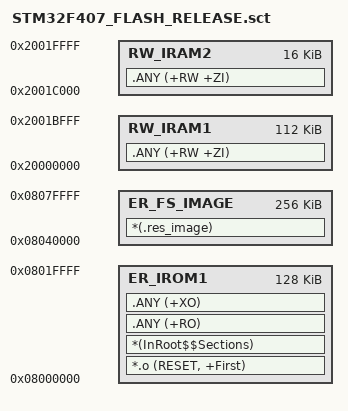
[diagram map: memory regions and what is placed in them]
; *************************************************************
; *** Scatter-Loading Description File generated by uVision ***
; *************************************************************

LR_IROM1 0x08000000 0x0020000  {    ; load region size_region
  ER_IROM1 0x08000000 0x0020000  {  ; load address = execution address
   *.o (RESET, +First)
   *(InRoot$$Sections)
   .ANY (+RO)
   .ANY (+XO)
  }
  RW_IRAM1 0x20000000 0x0001C000  {  ; RW data
   .ANY (+RW +ZI)
  }
  RW_IRAM2 0x2001C000 0x00004000  {
   .ANY (+RW +ZI)
  }
}

; ---------------- on-chip flash FATFS disk image (pre-built resources) ---------
; g_res_image (.res_image section) generated by tools/make_res_image.py is
; flashed at FLASH_DISK_BASE_ADDR. Address/size must match FLASH_DISK_BASE_ADDR
; (0x08040000) / FLASH_DISK_SIZE (0x00040000) in User/fs/flash_disk.h.
; The image is downloaded together with the firmware; at run time FatFs and
; USB MSC still access this region via flash_disk.c, the image is just the
; initial content. Code region (LR_IROM1) stays 128KB, swap sector S5
; (0x08020000..0x0803FFFF) is left out of the image on purpose.
FS_IMAGE 0x08040000 0x00040000  {
  ER_FS_IMAGE 0x08040000 0x00040000  {
    *(.res_image)
  }
}

